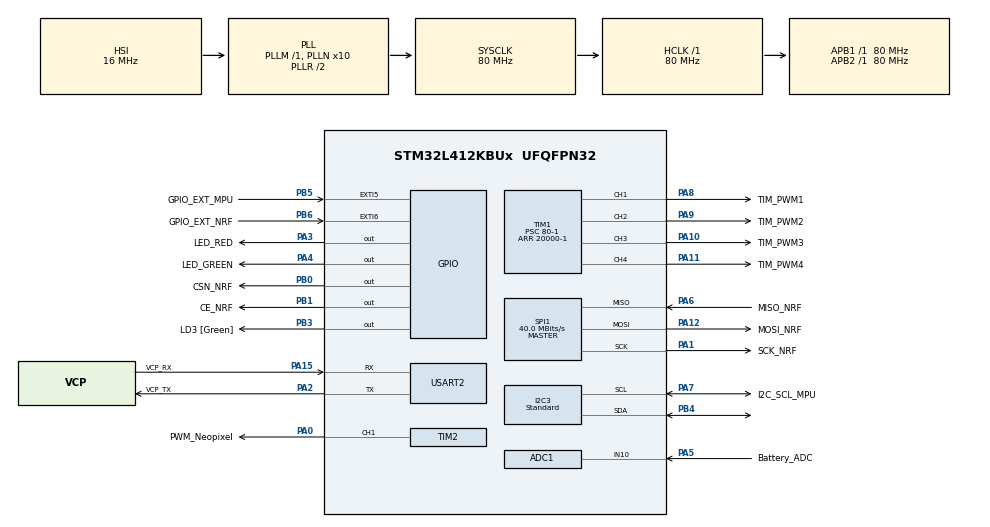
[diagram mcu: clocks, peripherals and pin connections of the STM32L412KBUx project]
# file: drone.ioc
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ADC1.Channel-3\#ChannelRegularConversion=ADC_CHANNEL_10
ADC1.NbrOfConversionFlag=1
ADC1.OffsetNumber-3\#ChannelRegularConversion=ADC_OFFSET_NONE
ADC1.Rank-3\#ChannelRegularConversion=1
ADC1.SamplingTime-3\#ChannelRegularConversion=ADC_SAMPLETIME_2CYCLES_5
ADC1.master=1
Dma.Request0=TIM2_CH1
Dma.TIM2_CH1.0.Direction=DMA_PERIPH_TO_MEMORY
Dma.TIM2_CH1.0.Instance=DMA1_Channel5
Dma.TIM2_CH1.0.MemDataAlignment=DMA_MDATAALIGN_WORD
Dma.TIM2_CH1.0.MemInc=DMA_MINC_ENABLE
Dma.TIM2_CH1.0.Mode=DMA_NORMAL
Dma.TIM2_CH1.0.PeriphDataAlignment=DMA_PDATAALIGN_WORD
Dma.TIM2_CH1.0.PeriphInc=DMA_PINC_DISABLE
Dma.TIM2_CH1.0.Priority=DMA_PRIORITY_VERY_HIGH
I2C3.I2C_Speed_Mode=I2C_Standard
I2C3.Timing=0x10909CEC
Mcu.Family=STM32L4
Mcu.Name=STM32L412KBUx
Mcu.Package=UFQFPN32
NVIC.DMA1_Channel5_IRQn=true\:0\:0\:false\:false\:true\:false\:true\:true
NVIC.PriorityGroup=NVIC_PRIORITYGROUP_4
PA0-CK_IN.GPIO_Label=PWM_Neopixel
PA0-CK_IN.Signal=S_TIM2_CH1
PA1.GPIO_Label=SCK_NRF
PA1.Mode=Full_Duplex_Master
PA1.Signal=SPI1_SCK
PA10.GPIO_Label=TIM_PWM3
PA10.Signal=S_TIM1_CH3
PA11.GPIO_Label=TIM_PWM4
PA11.Signal=S_TIM1_CH4
PA12.GPIO_Label=MOSI_NRF
PA12.Mode=Full_Duplex_Master
PA12.Signal=SPI1_MOSI
PA13\ (JTMS/SWDIO).GPIO_Label=SWDIO
PA13\ (JTMS/SWDIO).Mode=Serial_Wire
PA13\ (JTMS/SWDIO).Signal=SYS_JTMS-SWDIO
PA14\ (JTCK/SWCLK).GPIO_Label=SWCLK
PA14\ (JTCK/SWCLK).Mode=Serial_Wire
PA14\ (JTCK/SWCLK).Signal=SYS_JTCK-SWCLK
PA15\ (JTDI).GPIO_Label=VCP_RX
PA15\ (JTDI).Mode=Asynchronous
PA15\ (JTDI).Signal=USART2_RX
PA2.GPIO_Label=VCP_TX
PA2.Mode=Asynchronous
PA2.Signal=USART2_TX
PA3.GPIO_Label=LED_RED
PA3.Signal=GPIO_Output
PA4.GPIO_Label=LED_GREEN
PA4.Signal=GPIO_Output
PA5.GPIO_Label=Battery_ADC
PA5.Signal=ADCx_IN10
PA6.GPIO_Label=MISO_NRF
PA6.Mode=Full_Duplex_Master
PA6.Signal=SPI1_MISO
PA7.GPIO_Label=I2C_SCL_MPU
PA7.Mode=I2C
PA7.Signal=I2C3_SCL
PA8.GPIO_Label=TIM_PWM1
PA8.Signal=S_TIM1_CH1
PA9.GPIO_Label=TIM_PWM2
PA9.Signal=S_TIM1_CH2
PB0.GPIO_Label=CSN_NRF
PB0.Signal=GPIO_Output
PB1.GPIO_Label=CE_NRF
PB1.Signal=GPIO_Output
PB3\ (JTDO/TRACESWO).GPIO_Label=LD3 [Green]
PB3\ (JTDO/TRACESWO).GPIO_Speed=GPIO_SPEED_FREQ_LOW
PB3\ (JTDO/TRACESWO).Signal=GPIO_Output
PB4\ (NJTRST).Mode=I2C
PB4\ (NJTRST).Signal=I2C3_SDA
PB5.GPIO_Label=GPIO_EXT_MPU
PB5.Signal=GPXTI5
PB6.GPIO_Label=GPIO_EXT_NRF
PB6.Signal=GPXTI6
PC14-OSC32_IN\ (PC14).Mode=LSE-External-Oscillator
PC14-OSC32_IN\ (PC14).Signal=RCC_OSC32_IN
PC15-OSC32_OUT\ (PC15).Mode=LSE-External-Oscillator
PC15-OSC32_OUT\ (PC15).Signal=RCC_OSC32_OUT
ProjectManager.HeapSize=0x200
ProjectManager.StackSize=0x400
ProjectManager.TargetToolchain=STM32CubeIDE
RCC.ADCFreq_Value=80000000
RCC.AHBFreq_Value=80000000
RCC.APB1Freq_Value=80000000
RCC.APB1TimFreq_Value=80000000
RCC.APB2Freq_Value=80000000
RCC.APB2TimFreq_Value=80000000
RCC.CortexFreq_Value=80000000
RCC.FLatency=FLASH_LATENCY_4
RCC.HCLKFreq_Value=80000000
RCC.HSE_VALUE=8000000
RCC.HSI48_VALUE=48000000
RCC.HSICalibrationValue=16
RCC.HSI_VALUE=16000000
RCC.MSIClockRange=RCC_MSIRANGE_11
RCC.MSI_VALUE=48000000
RCC.PLLN=10
RCC.PLLSourceVirtual=RCC_PLLSOURCE_HSI
RCC.SYSCLKFreq_VALUE=80000000
RCC.SYSCLKSource=RCC_SYSCLKSOURCE_PLLCLK
RCC.USBFreq_Value=48000000
RCC.VCOOutputFreq_Value=160000000
SH.ADCx_IN10.0=ADC1_IN10,IN10-Single-Ended
SH.S_TIM1_CH1.0=TIM1_CH1,PWM Generation1 CH1
SH.S_TIM1_CH2.0=TIM1_CH2,PWM Generation2 CH2
SH.S_TIM1_CH3.0=TIM1_CH3,PWM Generation3 CH3
SH.S_TIM1_CH4.0=TIM1_CH4,PWM Generation4 CH4
SH.S_TIM2_CH1.0=TIM2_CH1,PWM Generation1 CH1
SPI1.CalculateBaudRate=40.0 MBits/s
SPI1.Direction=SPI_DIRECTION_2LINES
SPI1.Mode=SPI_MODE_MASTER
SPI1.VirtualType=VM_MASTER
TIM1.Channel-PWM\ Generation1\ CH1=TIM_CHANNEL_1
TIM1.Channel-PWM\ Generation2\ CH2=TIM_CHANNEL_2
TIM1.Channel-PWM\ Generation3\ CH3=TIM_CHANNEL_3
TIM1.Channel-PWM\ Generation4\ CH4=TIM_CHANNEL_4
<<<<<<< Updated upstream
=======
TIM1.Period=20000-1
TIM1.Prescaler=80-1
TIM1.Pulse-PWM\ Generation1\ CH1=0
>>>>>>> Stashed changes
TIM2.Channel-PWM\ Generation1\ CH1=TIM_CHANNEL_1
USART2.VirtualMode-Asynchronous=VM_ASYNC
VP_TIM1_VS_ClockSourceINT.Mode=Internal
VP_TIM2_VS_ClockSourceINT.Mode=Internal
board=NUCLEO-L412KB

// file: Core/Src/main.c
/* USER CODE BEGIN Header */
/**
  ******************************************************************************
  * @file           : main.c
  * @brief          : Main program body
  ******************************************************************************
  * @attention
  *
  * Copyright (c) 2023 STMicroelectronics.
  * All rights reserved.
  *
  * This software is licensed under terms that can be found in the LICENSE file
  * in the root directory of this software component.
  * If no LICENSE file comes with this software, it is provided AS-IS.
  *
  ******************************************************************************
  */
/* USER CODE END Header */
#include "main.h"
#include "adc.h"
#include "dma.h"
#include "i2c.h"
#include "spi.h"
#include "tim.h"
#include "usart.h"
#include "gpio.h"

/* USER CODE BEGIN PD */
#define RPM_Min 1000
#define RPM_Max 1050

/* USER CODE END PD */

void SystemClock_Config(void);

int main(void)
{

  /* MCU Configuration--------------------------------------------------------*/

  /* Reset of all peripherals, Initializes the Flash interface and the Systick. */
  HAL_Init();

  /* Configure the system clock */
  SystemClock_Config();

  /* Initialize all configured peripherals */
  MX_GPIO_Init();
  MX_DMA_Init();
  MX_USART2_UART_Init();
  MX_SPI1_Init();
  MX_ADC1_Init();
  MX_I2C3_Init();
  MX_TIM1_Init();
  MX_TIM2_Init();
  /* USER CODE BEGIN 2 */

  HAL_TIM_PWM_Start(&htim1,TIM_CHANNEL_1);

  //Initialisation du moteur
  __HAL_TIM_SET_COMPARE(&htim1, TIM_CHANNEL_1, RPM_Min);
  HAL_Delay(20); // Attente de 20 ms

  /* USER CODE END 2 */

  /* Infinite loop */
  /* USER CODE BEGIN WHILE */
  while (1)
  {
    // for(int i = RPM_Min; i <= RPM_Max; i++){
	  //     __HAL_TIM_SET_COMPARE(&htim1, TIM_CHANNEL_1, i);
		//     HAL_Delay(20); // Attente 20 ms entre chaque étape de progression
	  // }

	  // HAL_Delay(50); // Maintien en vol pendant 5 secondes

	  // for(int i = RPM_Max ; i >= RPM_Min; i--){
	  //     __HAL_TIM_SET_COMPARE(&htim1, TIM_CHANNEL_1, i);
		//     HAL_Delay(20); // Attente 20 ms entre chaque étape de progression
	  // }
  for(int i = RPM_Min; i <= 1070; i++){
   __HAL_TIM_SET_COMPARE(&htim1, TIM_CHANNEL_1, i);
   HAL_Delay(20); // Attente 20 ms entre chaque étape de progression

  }
    HAL_Delay(2000);
    // Arrête la génération du signal PWM
	  HAL_TIM_PWM_Stop(&htim1, TIM_CHANNEL_1);

    /* USER CODE END WHILE */

  }
}

void SystemClock_Config(void)
{
  RCC_OscInitTypeDef RCC_OscInitStruct = {0};
  RCC_ClkInitTypeDef RCC_ClkInitStruct = {0};

  /** Configure the main internal regulator output voltage
  */
  if (HAL_PWREx_ControlVoltageScaling(PWR_REGULATOR_VOLTAGE_SCALE1) != HAL_OK)
  {
    Error_Handler();
  }

  /** Initializes the RCC Oscillators according to the specified parameters
  * in the RCC_OscInitTypeDef structure.
  */
  RCC_OscInitStruct.OscillatorType = RCC_OSCILLATORTYPE_HSI;
  RCC_OscInitStruct.HSIState = RCC_HSI_ON;
  RCC_OscInitStruct.HSICalibrationValue = 16;
  RCC_OscInitStruct.PLL.PLLState = RCC_PLL_ON;
  RCC_OscInitStruct.PLL.PLLSource = RCC_PLLSOURCE_HSI;
  RCC_OscInitStruct.PLL.PLLM = 1;
  RCC_OscInitStruct.PLL.PLLN = 10;
  RCC_OscInitStruct.PLL.PLLQ = RCC_PLLQ_DIV2;
  RCC_OscInitStruct.PLL.PLLR = RCC_PLLR_DIV2;
  if (HAL_RCC_OscConfig(&RCC_OscInitStruct) != HAL_OK)
  {
    Error_Handler();
  }

  /** Initializes the CPU, AHB and APB buses clocks
  */
  RCC_ClkInitStruct.ClockType = RCC_CLOCKTYPE_HCLK|RCC_CLOCKTYPE_SYSCLK
                              |RCC_CLOCKTYPE_PCLK1|RCC_CLOCKTYPE_PCLK2;
  RCC_ClkInitStruct.SYSCLKSource = RCC_SYSCLKSOURCE_PLLCLK;
  RCC_ClkInitStruct.AHBCLKDivider = RCC_SYSCLK_DIV1;
  RCC_ClkInitStruct.APB1CLKDivider = RCC_HCLK_DIV1;
  RCC_ClkInitStruct.APB2CLKDivider = RCC_HCLK_DIV1;

  if (HAL_RCC_ClockConfig(&RCC_ClkInitStruct, FLASH_LATENCY_4) != HAL_OK)
  {
    Error_Handler();
  }
}

void Error_Handler(void)
{
  __disable_irq();
  while (1)
  {
  }
}
